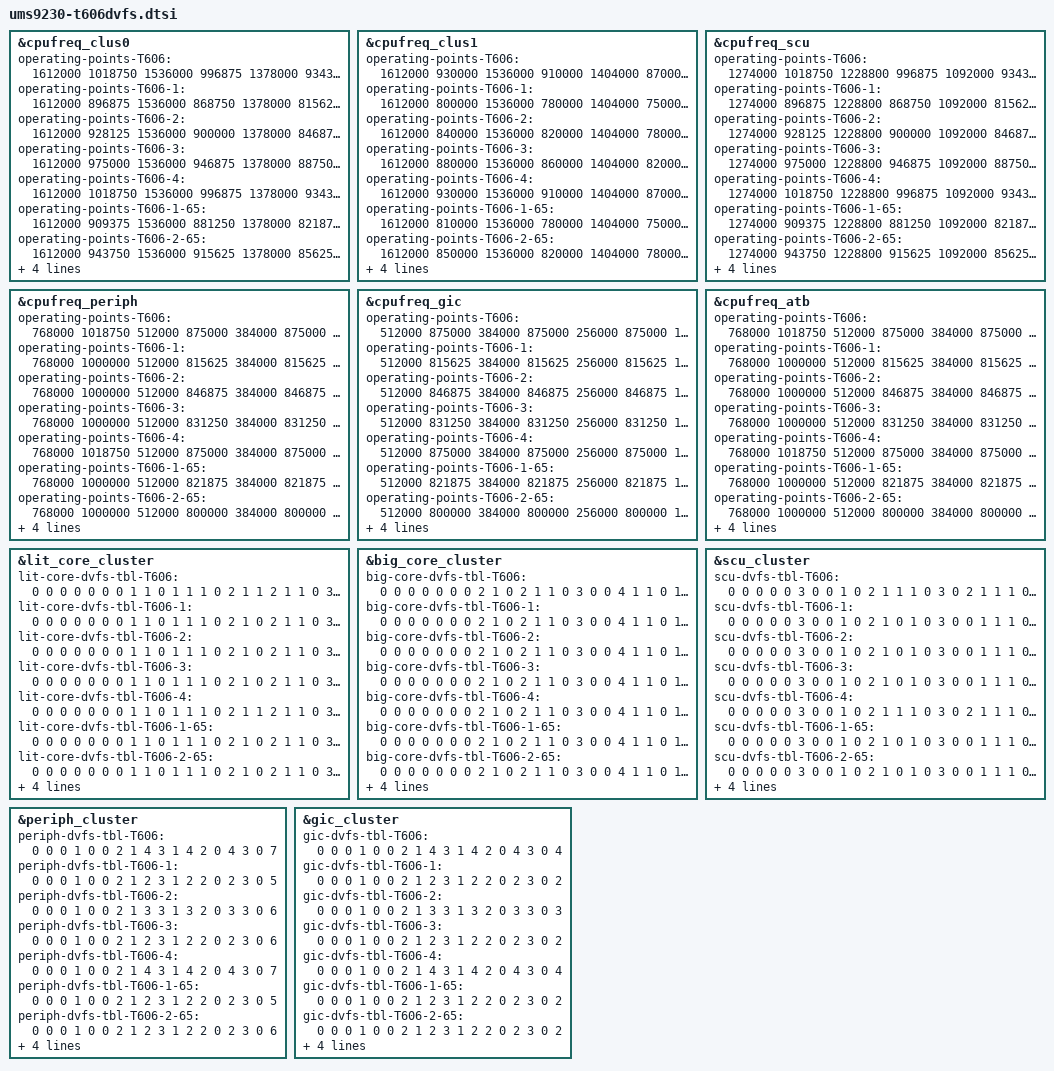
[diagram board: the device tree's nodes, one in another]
// SPDX-License-Identifier: (GPL-2.0+ OR MIT)
/*
 * Unisoc qogirl6 platform T606 SOC DVFS DTS file
 *
 * Copyright (C) 2021, Unisoc Communications Inc.
 */

#include "qogirl6.dtsi"
#include "ums9230.dtsi"

&cpufreq_clus0 {
	/* operating-points-T606-0-0
	 * T606/T616-soc_ver 0-binning 0-temp
	 */
	operating-points-T606 = <
		/* kHZ   uV */
		1612000 1018750
		1536000 996875
		1378000 934375
		1228800 875000
		1040000 787500
		884000  756250
		768000  718750
		614400  700000
	>;

	operating-points-T606-1 = <
		/* kHZ   uV */
		1612000 896875
		1536000 868750
		1378000 815625
		1228800 762500
		1040000 700000
		884000  700000
		768000  700000
		614400  700000
	>;

	operating-points-T606-2 = <
		/* kHZ   uV */
		1612000 928125
		1536000 900000
		1378000 846875
		1228800 793750
		1040000 725000
		884000  700000
		768000  700000
		614400  700000
	>;

	operating-points-T606-3 = <
		/* kHZ   uV */
		1612000 975000
		1536000 946875
		1378000 887500
		1228800 831250
		1040000 762500
		884000  700000
		768000  700000
		614400  700000
	>;

	operating-points-T606-4 = <
		/* kHZ   uV */
		1612000 1018750
		1536000 996875
		1378000 934375
		1228800 875000
		1040000 787500
		884000  756250
		768000  718750
		614400  700000
	>;

	operating-points-T606-1-65 = <
		/* kHZ   uV */
		1612000 909375
		1536000 881250
		1378000 821875
		1228800 768750
		1040000 700000
		884000  700000
		768000  700000
		614400  700000
	>;

	operating-points-T606-2-65 = <
		/* kHZ   uV */
		1612000 943750
		1536000 915625
		1378000 856250
		1228800 800000
		1040000 728125
		884000  700000
		768000  700000
		614400  700000
	>;

	operating-points-T606-3-65 = <
		/* kHZ   uV */
		1612000 990625
		1536000 959375
		1378000 896875
		1228800 837500
		1040000 765625
		884000  700000
		768000  700000
		614400  700000
	>;

	operating-points-T606-4-65 = <
		/* kHZ   uV */
		1612000 1037500
		1536000 1012500
		1378000 946875
		1228800 884375
		1040000 793750
		884000  759375
		768000  721875
		614400  700000
	>;
};

&cpufreq_clus1 {
	operating-points-T606 = <
		/* kHZ   uV */
		1612000 930000
		1536000 910000
		1404000 870000
		1228800 810000
		1040000 750000
		768000  750000
	>;

	operating-points-T606-1 = <
		/* kHZ   uV */
		1612000 800000
		1536000 780000
		1404000 750000
		1228800 750000
		1040000 750000
		768000  750000
	>;

	operating-points-T606-2 = <
		/* kHZ   uV */
		1612000 840000
		1536000 820000
		1404000 780000
		1228800 750000
		1040000 750000
		768000  750000
	>;

	operating-points-T606-3 = <
		/* kHZ   uV */
		1612000 880000
		1536000 860000
		1404000 820000
		1228800 760000
		1040000 750000
		768000  750000
	>;

	operating-points-T606-4 = <
		/* kHZ   uV */
		1612000 930000
		1536000 910000
		1404000 870000
		1228800 810000
		1040000 750000
		768000  750000
	>;

	operating-points-T606-1-65 = <
		/* kHZ   uV */
		1612000 810000
		1536000 780000
		1404000 750000
		1228800 750000
		1040000 750000
		768000  750000
	>;

	operating-points-T606-2-65 = <
		/* kHZ   uV */
		1612000 850000
		1536000 820000
		1404000 780000
		1228800 750000
		1040000 750000
		768000  750000
	>;

	operating-points-T606-3-65 = <
		/* kHZ   uV */
		1612000 890000
		1536000 870000
		1404000 820000
		1228800 760000
		1040000 750000
		768000  750000
	>;

	operating-points-T606-4-65 = <
		/* kHZ   uV */
		1612000 940000
		1536000 920000
		1404000 870000
		1228800 820000
		1040000 750000
		768000  750000
	>;
};

&cpufreq_scu {
	operating-points-T606 = <
		/* kHZ   uV */
		1274000 1018750
		1228800 996875
		1092000 934375
		962000  875000
		768000  787500
		702000  756250
		614400  718750
		546000  700000
	>;

	operating-points-T606-1 = <
		/* kHZ   uV */
		1274000 896875
		1228800 868750
		1092000 815625
		962000  762500
		768000  700000
		702000  700000
		614400  700000
		546000  700000
	>;

	operating-points-T606-2 = <
		/* kHZ   uV */
		1274000 928125
		1228800 900000
		1092000 846875
		962000  793750
		768000  725000
		702000  700000
		614400  700000
		546000  700000
	>;

	operating-points-T606-3 = <
		/* kHZ   uV */
		1274000 975000
		1228800 946875
		1092000 887500
		962000  831250
		768000  762500
		702000  700000
		614400  700000
		546000  700000
	>;

	operating-points-T606-4 = <
		/* kHZ   uV */
		1274000 1018750
		1228800 996875
		1092000 934375
		962000  875000
		768000  787500
		702000  756250
		614400  718750
		546000  700000
	>;

	operating-points-T606-1-65 = <
		/* kHZ   uV */
		1274000 909375
		1228800 881250
		1092000 821875
		962000  768750
		768000  700000
		702000  700000
		614400  700000
		546000  700000
	>;

	operating-points-T606-2-65 = <
		/* kHZ   uV */
		1274000 943750
		1228800 915625
		1092000 856250
		962000  800000
		768000  728125
		702000  700000
		614400  700000
		546000  700000
	>;

	operating-points-T606-3-65 = <
		/* kHZ   uV */
		1274000 990625
		1228800 959375
		1092000 896875
		962000  837500
		768000  765625
		702000  700000
		614400  700000
		546000  700000
	>;

	operating-points-T606-4-65 = <
		/* kHZ   uV */
		1274000 1037500
		1228800 1012500
		1092000 946875
		962000  884375
		768000  793750
		702000  759375
		614400  721875
		546000  700000
	>;
};

&cpufreq_periph {
	operating-points-T606 = <
		/* kHZ   uV */
		768000  1018750
		512000  875000
		384000  875000
		256000  875000
		153600  700000
	>;

	operating-points-T606-1 = <
		/* kHZ   uV */
		768000  1000000
		512000  815625
		384000  815625
		256000  815625
		153600  700000
	>;

	operating-points-T606-2 = <
		/* kHZ   uV */
		768000  1000000
		512000  846875
		384000  846875
		256000  846875
		153600  700000
	>;

	operating-points-T606-3 = <
		/* kHZ   uV */
		768000  1000000
		512000  831250
		384000  831250
		256000  831250
		153600  700000
	>;

	operating-points-T606-4 = <
		/* kHZ   uV */
		768000  1018750
		512000  875000
		384000  875000
		256000  875000
		153600  700000
	>;

	operating-points-T606-1-65 = <
		/* kHZ   uV */
		768000  1000000
		512000  821875
		384000  821875
		256000  821875
		153600  700000
	>;

	operating-points-T606-2-65 = <
		/* kHZ   uV */
		768000  1000000
		512000  800000
		384000  800000
		256000  800000
		153600  700000
	>;

	operating-points-T606-3-65 = <
		/* kHZ   uV */
		768000  1000000
		512000  837500
		384000  837500
		256000  837500
		153600  700000
	>;

	operating-points-T606-4-65 = <
		/* kHZ   uV */
		768000  1012500
		512000  884375
		384000  884375
		256000  884375
		153600  700000
	>;
};

&cpufreq_gic {
	operating-points-T606 = <
		/* kHZ   uV */
		512000  875000
		384000  875000
		256000  875000
		192000  875000
		153600  700000
	>;

	operating-points-T606-1 = <
		/* kHZ   uV */
		512000  815625
		384000  815625
		256000  815625
		192000  815625
		153600  700000
	>;

	operating-points-T606-2 = <
		/* kHZ   uV */
		512000  846875
		384000  846875
		256000  846875
		192000  846875
		153600  700000
	>;

	operating-points-T606-3 = <
		/* kHZ   uV */
		512000  831250
		384000  831250
		256000  831250
		192000  831250
		153600  700000
	>;

	operating-points-T606-4 = <
		/* kHZ   uV */
		512000  875000
		384000  875000
		256000  875000
		192000  875000
		153600  700000
	>;

	operating-points-T606-1-65 = <
		/* kHZ   uV */
		512000  821875
		384000  821875
		256000  821875
		192000  821875
		153600  700000
	>;

	operating-points-T606-2-65 = <
		/* kHZ   uV */
		512000  800000
		384000  800000
		256000  800000
		192000  800000
		153600  700000
	>;

	operating-points-T606-3-65 = <
		/* kHZ   uV */
		512000  837500
		384000  837500
		256000  837500
		192000  837500
		153600  700000
	>;

	operating-points-T606-4-65 = <
		/* kHZ   uV */
		512000  884375
		384000  884375
		256000  884375
		192000  884375
		153600  700000
	>;
};

&cpufreq_atb {
	operating-points-T606 = <
		/* kHZ   uV */
		768000  1018750
		512000  875000
		384000  875000
		256000  700000
		153600  700000
	>;

	operating-points-T606-1 = <
		/* kHZ   uV */
		768000  1000000
		512000  815625
		384000  815625
		256000  700000
		153600  700000
	>;

	operating-points-T606-2 = <
		/* kHZ   uV */
		768000  1000000
		512000  846875
		384000  846875
		256000  700000
		153600  700000
	>;

	operating-points-T606-3 = <
		/* kHZ   uV */
		768000  1000000
		512000  831250
		384000  831250
		256000  700000
		153600  700000
	>;

	operating-points-T606-4 = <
		/* kHZ   uV */
		768000  1018750
		512000  875000
		384000  875000
		256000  700000
		153600  700000
	>;

	operating-points-T606-1-65 = <
		/* kHZ   uV */
		768000  1000000
		512000  821875
		384000  821875
		256000  700000
		153600  700000
	>;

	operating-points-T606-2-65 = <
		/* kHZ   uV */
		768000  1000000
		512000  800000
		384000  800000
		256000  700000
		153600  700000
	>;

	operating-points-T606-3-65 = <
		/* kHZ   uV */
		768000  1000000
		512000  837500
		384000  837500
		256000  700000
		153600  700000
	>;

	operating-points-T606-4-65 = <
		/* kHZ   uV */
		768000  1012500
		512000  884375
		384000  884375
		256000  700000
		153600  700000
	>;
};

&lit_core_cluster {
	/* lit-core-dvfs-tbl-T606-0-0
	 * T606/T616-soc_ver 0-binning 0-temp
	 * sel, div, vol, vote_scu, vote_peri, vote_gic, mpllx
	 */
	lit-core-dvfs-tbl-T606 = <
		0 0 0 0 0 0 0
		1 1 0 1 1 1 0
		2 1 1 2 1 1 0
		3 0 2 3 1 1 0
		3 0 3 4 1 1 1
		1 0 4 5 1 1 0
		3 0 5 6 4 4 2
		2 0 6 7 4 4 0
		3 0 7 8 4 5 3
		3 0 7 8 4 5 3
		3 0 7 8 4 5 3
	>;

	lit-core-dvfs-tbl-T606-1 = <
		0 0 0 0 0 0 0
		1 1 0 1 1 1 0
		2 1 0 2 1 1 0
		3 0 0 3 1 1 0
		3 0 0 4 1 1 1
		1 0 1 5 1 1 0
		3 0 2 6 4 4 2
		2 0 3 7 4 4 0
		3 0 4 8 4 5 3
		3 0 4 8 4 5 3
		3 0 4 8 4 5 3
	>;

	lit-core-dvfs-tbl-T606-2 = <
		0 0 0 0 0 0 0
		1 1 0 1 1 1 0
		2 1 0 2 1 1 0
		3 0 0 3 1 1 0
		3 0 1 4 1 1 1
		1 0 2 5 1 1 0
		3 0 3 6 4 4 2
		2 0 4 7 4 4 0
		3 0 5 8 4 5 3
		3 0 5 8 4 5 3
		3 0 5 8 4 5 3
	>;

	lit-core-dvfs-tbl-T606-3 = <
		0 0 0 0 0 0 0
		1 1 0 1 1 1 0
		2 1 0 2 1 1 0
		3 0 0 3 1 1 0
		3 0 1 4 1 1 1
		1 0 2 5 1 1 0
		3 0 3 6 4 4 2
		2 0 4 7 4 4 0
		3 0 5 8 4 5 3
		3 0 5 8 4 5 3
		3 0 5 8 4 5 3
	>;

	lit-core-dvfs-tbl-T606-4 = <
		0 0 0 0 0 0 0
		1 1 0 1 1 1 0
		2 1 1 2 1 1 0
		3 0 2 3 1 1 0
		3 0 3 4 1 1 1
		1 0 4 5 1 1 0
		3 0 5 6 4 4 2
		2 0 6 7 4 4 0
		3 0 7 8 4 5 3
		3 0 7 8 4 5 3
		3 0 7 8 4 5 3
	>;

	lit-core-dvfs-tbl-T606-1-65 = <
		0 0 0 0 0 0 0
		1 1 0 1 1 1 0
		2 1 0 2 1 1 0
		3 0 0 3 1 1 0
		3 0 0 4 1 1 1
		1 0 1 5 1 1 0
		3 0 2 6 4 4 2
		2 0 3 7 4 4 0
		3 0 4 8 4 5 3
		3 0 4 8 4 5 3
		3 0 4 8 4 5 3
	>;

	lit-core-dvfs-tbl-T606-2-65 = <
		0 0 0 0 0 0 0
		1 1 0 1 1 1 0
		2 1 0 2 1 1 0
		3 0 0 3 1 1 0
		3 0 1 4 1 1 1
		1 0 2 5 1 1 0
		3 0 3 6 4 4 2
		2 0 4 7 4 4 0
		3 0 5 8 4 5 3
		3 0 5 8 4 5 3
		3 0 5 8 4 5 3
	>;

	lit-core-dvfs-tbl-T606-3-65 = <
		0 0 0 0 0 0 0
		1 1 0 1 1 1 0
		2 1 0 2 1 1 0
		3 0 0 3 1 1 0
		3 0 1 4 1 1 1
		1 0 2 5 1 1 0
		3 0 3 6 4 4 2
		2 0 4 7 4 4 0
		3 0 5 8 4 5 3
		3 0 5 8 4 5 3
		3 0 5 8 4 5 3
	>;

	lit-core-dvfs-tbl-T606-4-65 = <
		0 0 0 0 0 0 0
		1 1 0 1 1 1 0
		2 1 1 2 1 1 0
		3 0 2 3 1 1 0
		3 0 3 4 1 1 1
		1 0 4 5 1 1 0
		3 0 5 6 4 4 2
		2 0 6 7 4 4 0
		3 0 7 8 4 5 3
		3 0 7 8 4 5 3
		3 0 7 8 4 5 3
	>;
};

&big_core_cluster {
	/* sel, div, vol, vote_scu, vote_peri, vote_gic, mpllx */
	big-core-dvfs-tbl-T606 = <
		0 0 0 0 0 0 0
		2 1 0 2 1 1 0
		3 0 0 4 1 1 0
		1 0 1 4 1 1 0
		3 0 2 6 4 4 1
		2 0 3 7 4 4 0
		3 0 4 8 4 5 2
		3 0 4 8 4 5 2
		3 0 4 8 4 5 2
		3 0 4 8 4 5 2
	>;

	big-core-dvfs-tbl-T606-1 = <
		0 0 0 0 0 0 0
		2 1 0 2 1 1 0
		3 0 0 4 1 1 0
		1 0 0 4 1 1 0
		3 0 0 6 4 4 1
		2 0 1 7 4 4 0
		3 0 2 8 4 5 2
		3 0 2 8 4 5 2
		3 0 2 8 4 5 2
		3 0 2 8 4 5 2
	>;

	big-core-dvfs-tbl-T606-2 = <
		0 0 0 0 0 0 0
		2 1 0 2 1 1 0
		3 0 0 4 1 1 0
		1 0 0 4 1 1 0
		3 0 1 6 4 4 1
		2 0 2 7 4 4 0
		3 0 3 8 4 5 2
		3 0 3 8 4 5 2
		3 0 3 8 4 5 2
		3 0 3 8 4 5 2
	>;

	big-core-dvfs-tbl-T606-3 = <
		0 0 0 0 0 0 0
		2 1 0 2 1 1 0
		3 0 0 4 1 1 0
		1 0 1 4 1 1 0
		3 0 2 6 4 4 1
		2 0 3 7 4 4 0
		3 0 4 8 4 5 2
		3 0 4 8 4 5 2
		3 0 4 8 4 5 2
		3 0 4 8 4 5 2
	>;

	big-core-dvfs-tbl-T606-4 = <
		0 0 0 0 0 0 0
		2 1 0 2 1 1 0
		3 0 0 4 1 1 0
		1 0 1 4 1 1 0
		3 0 2 6 4 4 1
		2 0 3 7 4 4 0
		3 0 4 8 4 5 2
		3 0 4 8 4 5 2
		3 0 4 8 4 5 2
		3 0 4 8 4 5 2
	>;

	big-core-dvfs-tbl-T606-1-65 = <
		0 0 0 0 0 0 0
		2 1 0 2 1 1 0
		3 0 0 4 1 1 0
		1 0 0 4 1 1 0
		3 0 0 6 4 4 1
		2 0 1 7 4 4 0
		3 0 2 8 4 5 2
		3 0 2 8 4 5 2
		3 0 2 8 4 5 2
		3 0 2 8 4 5 2
	>;

	big-core-dvfs-tbl-T606-2-65 = <
		0 0 0 0 0 0 0
		2 1 0 2 1 1 0
		3 0 0 4 1 1 0
		1 0 0 4 1 1 0
		3 0 1 6 4 4 1
		2 0 2 7 4 4 0
		3 0 3 8 4 5 2
		3 0 3 8 4 5 2
		3 0 3 8 4 5 2
		3 0 3 8 4 5 2
	>;

	big-core-dvfs-tbl-T606-3-65 = <
		0 0 0 0 0 0 0
		2 1 0 2 1 1 0
		3 0 0 4 1 1 0
		1 0 1 4 1 1 0
		3 0 2 6 4 4 1
		2 0 3 7 4 4 0
		3 0 4 8 4 5 2
		3 0 4 8 4 5 2
		3 0 4 8 4 5 2
		3 0 4 8 4 5 2
	>;

	big-core-dvfs-tbl-T606-4-65 = <
		0 0 0 0 0 0 0
		2 1 0 2 1 1 0
		3 0 0 4 1 1 0
		1 0 1 4 1 1 0
		3 0 2 6 4 4 1
		2 0 3 7 4 4 0
		3 0 4 8 4 5 2
		3 0 4 8 4 5 2
		3 0 4 8 4 5 2
		3 0 4 8 4 5 2
	>;
};

&scu_cluster {
	/* sel, div, vol, ace_div, mpllx */
	scu-dvfs-tbl-T606 = <
		0 0 0 0 0
		3 0 0 1 0
		2 1 1 1 0
		3 0 2 1 1
		1 0 3 1 0
		3 0 4 1 2
		3 0 5 1 3
		2 0 6 1 0
		3 0 7 1 4
		3 0 7 1 4
		3 0 7 1 4
	>;

	scu-dvfs-tbl-T606-1 = <
		0 0 0 0 0
		3 0 0 1 0
		2 1 0 1 0
		3 0 0 1 1
		1 0 0 1 0
		3 0 1 1 2
		3 0 2 1 3
		2 0 3 1 0
		3 0 4 1 4
		3 0 4 1 4
		3 0 4 1 4
	>;

	scu-dvfs-tbl-T606-2 = <
		0 0 0 0 0
		3 0 0 1 0
		2 1 0 1 0
		3 0 0 1 1
		1 0 1 1 0
		3 0 2 1 2
		3 0 3 1 3
		2 0 4 1 0
		3 0 5 1 4
		3 0 5 1 4
		3 0 5 1 4
	>;

	scu-dvfs-tbl-T606-3 = <
		0 0 0 0 0
		3 0 0 1 0
		2 1 0 1 0
		3 0 0 1 1
		1 0 1 1 0
		3 0 2 1 2
		3 0 3 1 3
		2 0 4 1 0
		3 0 5 1 4
		3 0 5 1 4
		3 0 5 1 4
	>;

	scu-dvfs-tbl-T606-4 = <
		0 0 0 0 0
		3 0 0 1 0
		2 1 1 1 0
		3 0 2 1 1
		1 0 3 1 0
		3 0 4 1 2
		3 0 5 1 3
		2 0 6 1 0
		3 0 7 1 4
		3 0 7 1 4
		3 0 7 1 4
	>;

	scu-dvfs-tbl-T606-1-65 = <
		0 0 0 0 0
		3 0 0 1 0
		2 1 0 1 0
		3 0 0 1 1
		1 0 0 1 0
		3 0 1 1 2
		3 0 2 1 3
		2 0 3 1 0
		3 0 4 1 4
		3 0 4 1 4
		3 0 4 1 4
	>;

	scu-dvfs-tbl-T606-2-65 = <
		0 0 0 0 0
		3 0 0 1 0
		2 1 0 1 0
		3 0 0 1 1
		1 0 1 1 0
		3 0 2 1 2
		3 0 3 1 3
		2 0 4 1 0
		3 0 5 1 4
		3 0 5 1 4
		3 0 5 1 4
	>;

	scu-dvfs-tbl-T606-3-65 = <
		0 0 0 0 0
		3 0 0 1 0
		2 1 0 1 0
		3 0 0 1 1
		1 0 1 1 0
		3 0 2 1 2
		3 0 3 1 3
		2 0 4 1 0
		3 0 5 1 4
		3 0 5 1 4
		3 0 5 1 4
	>;

	scu-dvfs-tbl-T606-4-65 = <
		0 0 0 0 0
		3 0 0 1 0
		2 1 1 1 0
		3 0 2 1 1
		1 0 3 1 0
		3 0 4 1 2
		3 0 5 1 3
		2 0 6 1 0
		3 0 7 1 4
		3 0 7 1 4
		3 0 7 1 4
	>;
};

&periph_cluster{
	/* sel, div, vol */
	periph-dvfs-tbl-T606 = <
		0 0 0
		1 0 0
		2 1 4
		3 1 4
		2 0 4
		3 0 7
	>;

	periph-dvfs-tbl-T606-1 = <
		0 0 0
		1 0 0
		2 1 2
		3 1 2
		2 0 2
		3 0 5
	>;

	periph-dvfs-tbl-T606-2 = <
		0 0 0
		1 0 0
		2 1 3
		3 1 3
		2 0 3
		3 0 6
	>;

	periph-dvfs-tbl-T606-3 = <
		0 0 0
		1 0 0
		2 1 2
		3 1 2
		2 0 2
		3 0 6
	>;

	periph-dvfs-tbl-T606-4 = <
		0 0 0
		1 0 0
		2 1 4
		3 1 4
		2 0 4
		3 0 7
	>;

	periph-dvfs-tbl-T606-1-65 = <
		0 0 0
		1 0 0
		2 1 2
		3 1 2
		2 0 2
		3 0 5
	>;

	periph-dvfs-tbl-T606-2-65 = <
		0 0 0
		1 0 0
		2 1 2
		3 1 2
		2 0 2
		3 0 6
	>;

	periph-dvfs-tbl-T606-3-65 = <
		0 0 0
		1 0 0
		2 1 2
		3 1 2
		2 0 2
		3 0 6
	>;

	periph-dvfs-tbl-T606-4-65 = <
		0 0 0
		1 0 0
		2 1 4
		3 1 4
		2 0 4
		3 0 6
	>;
};

&gic_cluster{
	/* sel, div, vol */
	gic-dvfs-tbl-T606 = <
		0 0 0
		1 0 0
		2 1 4
		3 1 4
		2 0 4
		3 0 4
	>;

	gic-dvfs-tbl-T606-1 = <
		0 0 0
		1 0 0
		2 1 2
		3 1 2
		2 0 2
		3 0 2
	>;

	gic-dvfs-tbl-T606-2 = <
		0 0 0
		1 0 0
		2 1 3
		3 1 3
		2 0 3
		3 0 3
	>;

	gic-dvfs-tbl-T606-3 = <
		0 0 0
		1 0 0
		2 1 2
		3 1 2
		2 0 2
		3 0 2
	>;

	gic-dvfs-tbl-T606-4 = <
		0 0 0
		1 0 0
		2 1 4
		3 1 4
		2 0 4
		3 0 4
	>;

	gic-dvfs-tbl-T606-1-65 = <
		0 0 0
		1 0 0
		2 1 2
		3 1 2
		2 0 2
		3 0 2
	>;

	gic-dvfs-tbl-T606-2-65 = <
		0 0 0
		1 0 0
		2 1 2
		3 1 2
		2 0 2
		3 0 2
	>;

	gic-dvfs-tbl-T606-3-65 = <
		0 0 0
		1 0 0
		2 1 2
		3 1 2
		2 0 2
		3 0 2
	>;

	gic-dvfs-tbl-T606-4-65 = <
		0 0 0
		1 0 0
		2 1 4
		3 1 4
		2 0 4
		3 0 4
	>;
};
